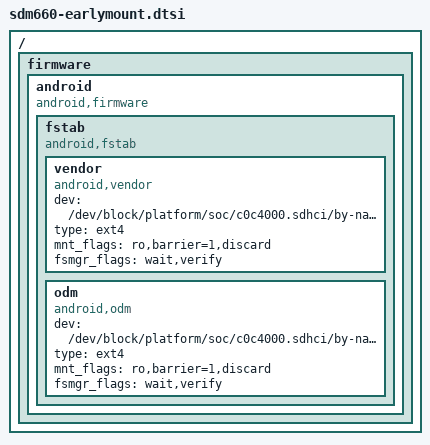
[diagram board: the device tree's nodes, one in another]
 /{
          firmware {
                  android {
                          compatible = "android,firmware";
                          fstab {
                                  compatible = "android,fstab";
                                  vendor {
                                          compatible = "android,vendor";
                                          dev = "/dev/block/platform/soc/c0c4000.sdhci/by-name/vendor";
                                          type = "ext4";
                                          mnt_flags = "ro,barrier=1,discard";
                                          fsmgr_flags = "wait,verify";
                                          status = "ok";
                                  };
                                 odm {
                                          compatible = "android,odm";
                                          dev = "/dev/block/platform/soc/c0c4000.sdhci/by-name/odm";
                                          type = "ext4";
                                          mnt_flags = "ro,barrier=1,discard";
                                          fsmgr_flags = "wait,verify";
                                          status = "ok";
                                  };
                          };
                  };
          };
  };
